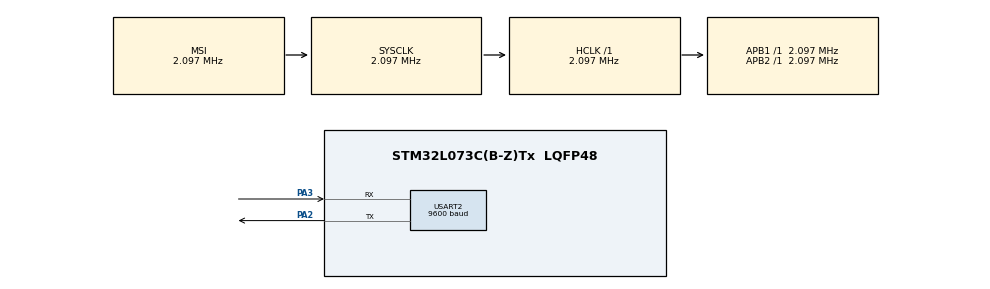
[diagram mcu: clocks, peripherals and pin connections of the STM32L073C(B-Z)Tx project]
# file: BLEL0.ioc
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Dma.Request0=USART2_RX
Dma.USART2_RX.0.Direction=DMA_PERIPH_TO_MEMORY
Dma.USART2_RX.0.Instance=DMA1_Channel5
Dma.USART2_RX.0.MemDataAlignment=DMA_MDATAALIGN_BYTE
Dma.USART2_RX.0.MemInc=DMA_MINC_ENABLE
Dma.USART2_RX.0.Mode=DMA_CIRCULAR
Dma.USART2_RX.0.PeriphDataAlignment=DMA_PDATAALIGN_BYTE
Dma.USART2_RX.0.PeriphInc=DMA_PINC_DISABLE
Dma.USART2_RX.0.Priority=DMA_PRIORITY_LOW
Mcu.Family=STM32L0
Mcu.Name=STM32L073C(B-Z)Tx
Mcu.Package=LQFP48
NVIC.DMA1_Channel4_5_6_7_IRQn=true\:0\:0\:false\:false\:true\:false\:true
PA2.Mode=Asynchronous
PA2.Signal=USART2_TX
PA3.Mode=Asynchronous
PA3.Signal=USART2_RX
PC14-OSC32_IN.Mode=LSE-External-Oscillator
PC14-OSC32_IN.Signal=RCC_OSC32_IN
PC15-OSC32_OUT.Mode=LSE-External-Oscillator
PC15-OSC32_OUT.Signal=RCC_OSC32_OUT
ProjectManager.HeapSize=0x200
ProjectManager.StackSize=0x400
ProjectManager.TargetToolchain=MDK-ARM V5
RCC.AHBFreq_Value=2097000
RCC.APB1Freq_Value=2097000
RCC.APB1TimFreq_Value=2097000
RCC.APB2Freq_Value=2097000
RCC.APB2TimFreq_Value=2097000
RCC.HSE_VALUE=8000000
RCC.HSI16_VALUE=16000000
RCC.HSI48_VALUE=48000000
RCC.HSI_VALUE=16000000
RCC.MSI_VALUE=2097000
RCC.SYSCLKFreq_VALUE=2097000
RCC.VCOOutputFreq_Value=48000000
USART2.BaudRate=9600
USART2.VirtualMode-Asynchronous=VM_ASYNC
board=custom

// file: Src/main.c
/* USER CODE BEGIN Header */
/**
  ******************************************************************************
  * @file           : main.c
  * @brief          : Main program body
  ******************************************************************************
  * @attention
  *
  * <h2><center>&copy; Copyright (c) 2019 STMicroelectronics.
  * All rights reserved.</center></h2>
  *
  * This software component is licensed by ST under BSD 3-Clause license,
  * the "License"; You may not use this file except in compliance with the
  * License. You may obtain a copy of the License at:
  *                        opensource.org/licenses/BSD-3-Clause
  *
  ******************************************************************************
  */
/* USER CODE END Header */

#include "main.h"

/* USER CODE BEGIN PD */
uint8_t BLEchck[5];
uint8_t BLErx[300];
/* USER CODE END PD */

UART_HandleTypeDef huart2;
DMA_HandleTypeDef hdma_usart2_rx;

void SystemClock_Config(void);
static void MX_GPIO_Init(void);
static void MX_DMA_Init(void);
static void MX_USART2_UART_Init(void);

int main(void)
{

  /* MCU Configuration--------------------------------------------------------*/

  /* Reset of all peripherals, Initializes the Flash interface and the Systick. */
  HAL_Init();

  /* Configure the system clock */
  SystemClock_Config();

  /* Initialize all configured peripherals */
  MX_GPIO_Init();
  MX_DMA_Init();
  MX_USART2_UART_Init();

  /* Infinite loop */
  /* USER CODE BEGIN WHILE */
  while (1)

  {

		uint8_t BLEwake[4] = "AT\r\n";
		uint8_t BLEat[9] = "AT+SCAN\r\n";

		HAL_UART_Transmit(&huart2, BLEwake, 4, 10); //wakeup
		HAL_Delay(100);
		HAL_UART_Transmit(&huart2, BLEwake, 4, 10); //check OK response
		//HAL_UART_Receive(&huart2,BLEchck,4,3000);
		HAL_UART_Receive_DMA(&huart2,BLEchck,5);

		//scan
		HAL_UART_Transmit(&huart2, BLEat, 9, 10);
		//HAL_UART_Receive(&huart4,BLErx,6,1000);
	//	HAL_UART_Receive(&huart4,BLErx,300,10000);
		HAL_UART_Receive_DMA(&huart2,BLErx,300);

    /* USER CODE END WHILE */

  }
}

void SystemClock_Config(void)
{
  RCC_OscInitTypeDef RCC_OscInitStruct = {0};
  RCC_ClkInitTypeDef RCC_ClkInitStruct = {0};
  RCC_PeriphCLKInitTypeDef PeriphClkInit = {0};

  /** Configure the main internal regulator output voltage
  */
  __HAL_PWR_VOLTAGESCALING_CONFIG(PWR_REGULATOR_VOLTAGE_SCALE1);
  /** Initializes the CPU, AHB and APB busses clocks
  */
  RCC_OscInitStruct.OscillatorType = RCC_OSCILLATORTYPE_MSI;
  RCC_OscInitStruct.MSIState = RCC_MSI_ON;
  RCC_OscInitStruct.MSICalibrationValue = 0;
  RCC_OscInitStruct.MSIClockRange = RCC_MSIRANGE_5;
  RCC_OscInitStruct.PLL.PLLState = RCC_PLL_NONE;
  if (HAL_RCC_OscConfig(&RCC_OscInitStruct) != HAL_OK)
  {
    Error_Handler();
  }
  /** Initializes the CPU, AHB and APB busses clocks
  */
  RCC_ClkInitStruct.ClockType = RCC_CLOCKTYPE_HCLK|RCC_CLOCKTYPE_SYSCLK
                              |RCC_CLOCKTYPE_PCLK1|RCC_CLOCKTYPE_PCLK2;
  RCC_ClkInitStruct.SYSCLKSource = RCC_SYSCLKSOURCE_MSI;
  RCC_ClkInitStruct.AHBCLKDivider = RCC_SYSCLK_DIV1;
  RCC_ClkInitStruct.APB1CLKDivider = RCC_HCLK_DIV1;
  RCC_ClkInitStruct.APB2CLKDivider = RCC_HCLK_DIV1;

  if (HAL_RCC_ClockConfig(&RCC_ClkInitStruct, FLASH_LATENCY_0) != HAL_OK)
  {
    Error_Handler();
  }
  PeriphClkInit.PeriphClockSelection = RCC_PERIPHCLK_USART2;
  PeriphClkInit.Usart2ClockSelection = RCC_USART2CLKSOURCE_PCLK1;
  if (HAL_RCCEx_PeriphCLKConfig(&PeriphClkInit) != HAL_OK)
  {
    Error_Handler();
  }
}

static void MX_USART2_UART_Init(void)
{

  huart2.Instance = USART2;
  huart2.Init.BaudRate = 9600;
  huart2.Init.WordLength = UART_WORDLENGTH_8B;
  huart2.Init.StopBits = UART_STOPBITS_1;
  huart2.Init.Parity = UART_PARITY_NONE;
  huart2.Init.Mode = UART_MODE_TX_RX;
  huart2.Init.HwFlowCtl = UART_HWCONTROL_NONE;
  huart2.Init.OverSampling = UART_OVERSAMPLING_16;
  huart2.Init.OneBitSampling = UART_ONE_BIT_SAMPLE_DISABLE;
  huart2.AdvancedInit.AdvFeatureInit = UART_ADVFEATURE_NO_INIT;
  if (HAL_UART_Init(&huart2) != HAL_OK)
  {
    Error_Handler();
  }

}

static void MX_DMA_Init(void)
{

  /* DMA controller clock enable */
  __HAL_RCC_DMA1_CLK_ENABLE();

  /* DMA interrupt init */
  /* DMA1_Channel4_5_6_7_IRQn interrupt configuration */
  HAL_NVIC_SetPriority(DMA1_Channel4_5_6_7_IRQn, 0, 0);
  HAL_NVIC_EnableIRQ(DMA1_Channel4_5_6_7_IRQn);

}

static void MX_GPIO_Init(void)
{

  /* GPIO Ports Clock Enable */
  __HAL_RCC_GPIOC_CLK_ENABLE();
  __HAL_RCC_GPIOA_CLK_ENABLE();

}

void Error_Handler(void)
{
}

/************************ (C) COPYRIGHT STMicroelectronics *****END OF FILE****/
